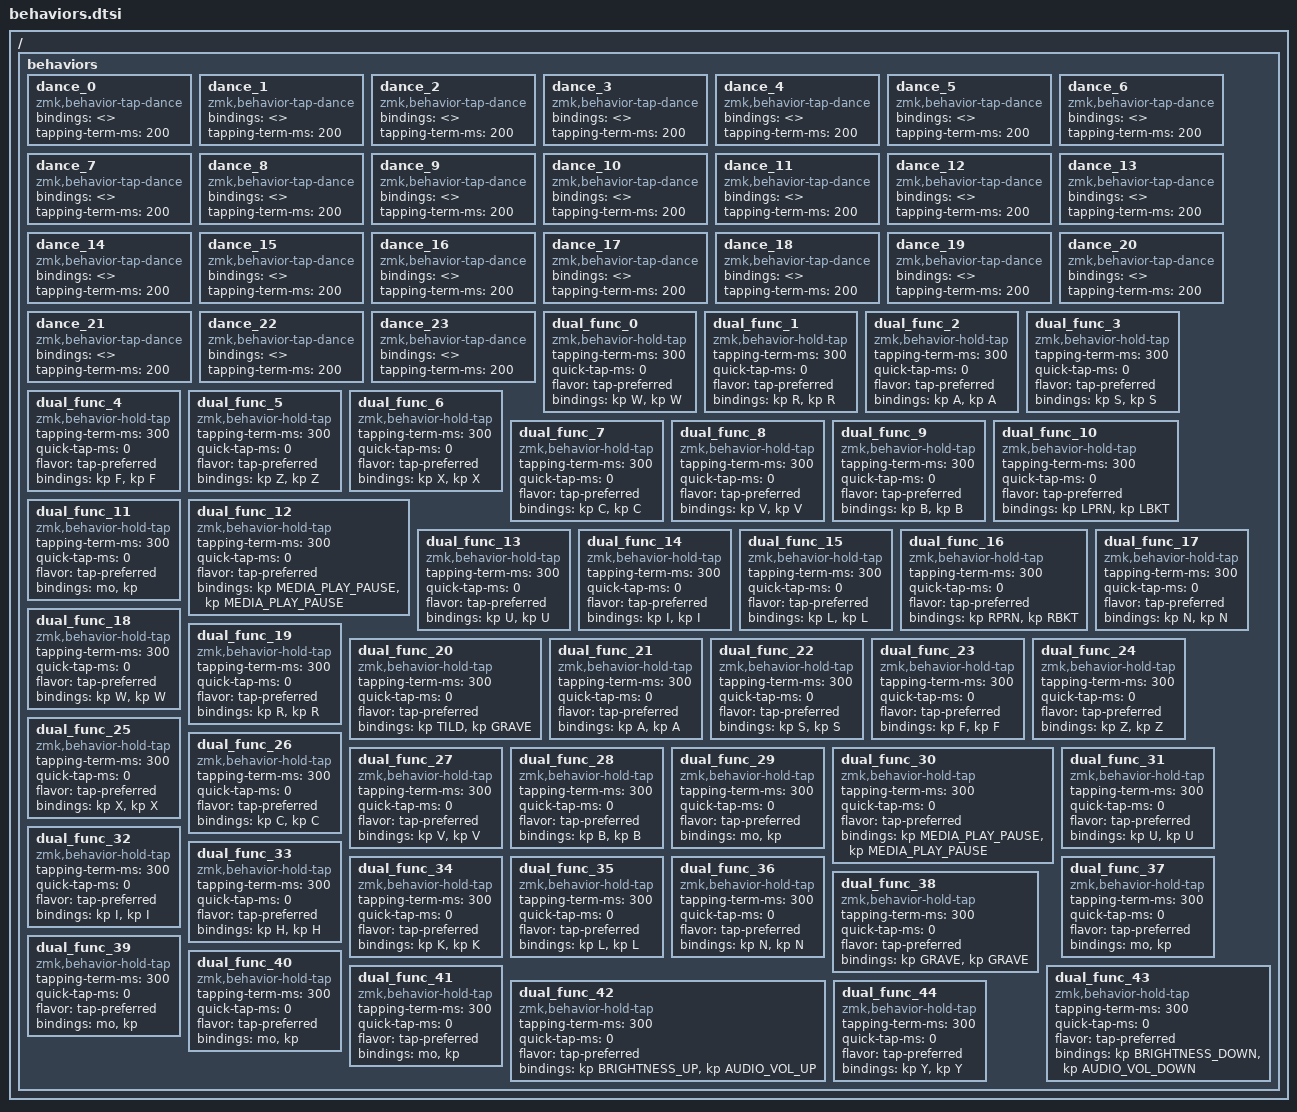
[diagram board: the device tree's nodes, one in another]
// Auto-generated by qmk_to_zmk.py - Complete behaviors conversion
#include <dt-bindings/zmk/keys.h>

/ {
    behaviors {
        dance_0: dance_0 {
            compatible = "zmk,behavior-tap-dance";
            #binding-cells = <0>;
            bindings = <>;
            tapping-term-ms = <200>;
        };

        dance_1: dance_1 {
            compatible = "zmk,behavior-tap-dance";
            #binding-cells = <0>;
            bindings = <>;
            tapping-term-ms = <200>;
        };

        dance_2: dance_2 {
            compatible = "zmk,behavior-tap-dance";
            #binding-cells = <0>;
            bindings = <>;
            tapping-term-ms = <200>;
        };

        dance_3: dance_3 {
            compatible = "zmk,behavior-tap-dance";
            #binding-cells = <0>;
            bindings = <>;
            tapping-term-ms = <200>;
        };

        dance_4: dance_4 {
            compatible = "zmk,behavior-tap-dance";
            #binding-cells = <0>;
            bindings = <>;
            tapping-term-ms = <200>;
        };

        dance_5: dance_5 {
            compatible = "zmk,behavior-tap-dance";
            #binding-cells = <0>;
            bindings = <>;
            tapping-term-ms = <200>;
        };

        dance_6: dance_6 {
            compatible = "zmk,behavior-tap-dance";
            #binding-cells = <0>;
            bindings = <>;
            tapping-term-ms = <200>;
        };

        dance_7: dance_7 {
            compatible = "zmk,behavior-tap-dance";
            #binding-cells = <0>;
            bindings = <>;
            tapping-term-ms = <200>;
        };

        dance_8: dance_8 {
            compatible = "zmk,behavior-tap-dance";
            #binding-cells = <0>;
            bindings = <>;
            tapping-term-ms = <200>;
        };

        dance_9: dance_9 {
            compatible = "zmk,behavior-tap-dance";
            #binding-cells = <0>;
            bindings = <>;
            tapping-term-ms = <200>;
        };

        dance_10: dance_10 {
            compatible = "zmk,behavior-tap-dance";
            #binding-cells = <0>;
            bindings = <>;
            tapping-term-ms = <200>;
        };

        dance_11: dance_11 {
            compatible = "zmk,behavior-tap-dance";
            #binding-cells = <0>;
            bindings = <>;
            tapping-term-ms = <200>;
        };

        dance_12: dance_12 {
            compatible = "zmk,behavior-tap-dance";
            #binding-cells = <0>;
            bindings = <>;
            tapping-term-ms = <200>;
        };

        dance_13: dance_13 {
            compatible = "zmk,behavior-tap-dance";
            #binding-cells = <0>;
            bindings = <>;
            tapping-term-ms = <200>;
        };

        dance_14: dance_14 {
            compatible = "zmk,behavior-tap-dance";
            #binding-cells = <0>;
            bindings = <>;
            tapping-term-ms = <200>;
        };

        dance_15: dance_15 {
            compatible = "zmk,behavior-tap-dance";
            #binding-cells = <0>;
            bindings = <>;
            tapping-term-ms = <200>;
        };

        dance_16: dance_16 {
            compatible = "zmk,behavior-tap-dance";
            #binding-cells = <0>;
            bindings = <>;
            tapping-term-ms = <200>;
        };

        dance_17: dance_17 {
            compatible = "zmk,behavior-tap-dance";
            #binding-cells = <0>;
            bindings = <>;
            tapping-term-ms = <200>;
        };

        dance_18: dance_18 {
            compatible = "zmk,behavior-tap-dance";
            #binding-cells = <0>;
            bindings = <>;
            tapping-term-ms = <200>;
        };

        dance_19: dance_19 {
            compatible = "zmk,behavior-tap-dance";
            #binding-cells = <0>;
            bindings = <>;
            tapping-term-ms = <200>;
        };

        dance_20: dance_20 {
            compatible = "zmk,behavior-tap-dance";
            #binding-cells = <0>;
            bindings = <>;
            tapping-term-ms = <200>;
        };

        dance_21: dance_21 {
            compatible = "zmk,behavior-tap-dance";
            #binding-cells = <0>;
            bindings = <>;
            tapping-term-ms = <200>;
        };

        dance_22: dance_22 {
            compatible = "zmk,behavior-tap-dance";
            #binding-cells = <0>;
            bindings = <>;
            tapping-term-ms = <200>;
        };

        dance_23: dance_23 {
            compatible = "zmk,behavior-tap-dance";
            #binding-cells = <0>;
            bindings = <>;
            tapping-term-ms = <200>;
        };

        dual_func_0: dual_func_0 {
            compatible = "zmk,behavior-hold-tap";
            #binding-cells = <2>;
            tapping-term-ms = <300>;
            quick-tap-ms = <0>;
            flavor = "tap-preferred";
            bindings = <&mo>, <&kp>;
        };

        dual_func_1: dual_func_1 {
            compatible = "zmk,behavior-hold-tap";
            #binding-cells = <2>;
            tapping-term-ms = <300>;
            quick-tap-ms = <0>;
            flavor = "tap-preferred";
            bindings = <&mo>, <&kp>;
        };

        dual_func_2: dual_func_2 {
            compatible = "zmk,behavior-hold-tap";
            #binding-cells = <2>;
            tapping-term-ms = <300>;
            quick-tap-ms = <0>;
            flavor = "tap-preferred";
            bindings = <&mo>, <&kp>;
        };

        dual_func_3: dual_func_3 {
            compatible = "zmk,behavior-hold-tap";
            #binding-cells = <2>;
            tapping-term-ms = <300>;
            quick-tap-ms = <0>;
            flavor = "tap-preferred";
            bindings = <&mo>, <&kp>;
        };

        dual_func_4: dual_func_4 {
            compatible = "zmk,behavior-hold-tap";
            #binding-cells = <2>;
            tapping-term-ms = <300>;
            quick-tap-ms = <0>;
            flavor = "tap-preferred";
            bindings = <&mo>, <&kp>;
        };

        dual_func_5: dual_func_5 {
            compatible = "zmk,behavior-hold-tap";
            #binding-cells = <2>;
            tapping-term-ms = <300>;
            quick-tap-ms = <0>;
            flavor = "tap-preferred";
            bindings = <&mo>, <&kp>;
        };

        dual_func_6: dual_func_6 {
            compatible = "zmk,behavior-hold-tap";
            #binding-cells = <2>;
            tapping-term-ms = <300>;
            quick-tap-ms = <0>;
            flavor = "tap-preferred";
            bindings = <&mo>, <&kp>;
        };

        dual_func_7: dual_func_7 {
            compatible = "zmk,behavior-hold-tap";
            #binding-cells = <2>;
            tapping-term-ms = <300>;
            quick-tap-ms = <0>;
            flavor = "tap-preferred";
            bindings = <&mo>, <&kp>;
        };

        dual_func_8: dual_func_8 {
            compatible = "zmk,behavior-hold-tap";
            #binding-cells = <2>;
            tapping-term-ms = <300>;
            quick-tap-ms = <0>;
            flavor = "tap-preferred";
            bindings = <&mo>, <&kp>;
        };

        dual_func_9: dual_func_9 {
            compatible = "zmk,behavior-hold-tap";
            #binding-cells = <2>;
            tapping-term-ms = <300>;
            quick-tap-ms = <0>;
            flavor = "tap-preferred";
            bindings = <&mo>, <&kp>;
        };

        dual_func_10: dual_func_10 {
            compatible = "zmk,behavior-hold-tap";
            #binding-cells = <2>;
            tapping-term-ms = <300>;
            quick-tap-ms = <0>;
            flavor = "tap-preferred";
            bindings = <&mo>, <&kp>;
        };

        dual_func_11: dual_func_11 {
            compatible = "zmk,behavior-hold-tap";
            #binding-cells = <2>;
            tapping-term-ms = <300>;
            quick-tap-ms = <0>;
            flavor = "tap-preferred";
            bindings = <&mo>, <&kp>;
        };

        dual_func_12: dual_func_12 {
            compatible = "zmk,behavior-hold-tap";
            #binding-cells = <2>;
            tapping-term-ms = <300>;
            quick-tap-ms = <0>;
            flavor = "tap-preferred";
            bindings = <&mo>, <&kp>;
        };

        dual_func_13: dual_func_13 {
            compatible = "zmk,behavior-hold-tap";
            #binding-cells = <2>;
            tapping-term-ms = <300>;
            quick-tap-ms = <0>;
            flavor = "tap-preferred";
            bindings = <&mo>, <&kp>;
        };

        dual_func_14: dual_func_14 {
            compatible = "zmk,behavior-hold-tap";
            #binding-cells = <2>;
            tapping-term-ms = <300>;
            quick-tap-ms = <0>;
            flavor = "tap-preferred";
            bindings = <&mo>, <&kp>;
        };

        dual_func_15: dual_func_15 {
            compatible = "zmk,behavior-hold-tap";
            #binding-cells = <2>;
            tapping-term-ms = <300>;
            quick-tap-ms = <0>;
            flavor = "tap-preferred";
            bindings = <&mo>, <&kp>;
        };

        dual_func_16: dual_func_16 {
            compatible = "zmk,behavior-hold-tap";
            #binding-cells = <2>;
            tapping-term-ms = <300>;
            quick-tap-ms = <0>;
            flavor = "tap-preferred";
            bindings = <&mo>, <&kp>;
        };

        dual_func_17: dual_func_17 {
            compatible = "zmk,behavior-hold-tap";
            #binding-cells = <2>;
            tapping-term-ms = <300>;
            quick-tap-ms = <0>;
            flavor = "tap-preferred";
            bindings = <&mo>, <&kp>;
        };

        dual_func_18: dual_func_18 {
            compatible = "zmk,behavior-hold-tap";
            #binding-cells = <2>;
            tapping-term-ms = <300>;
            quick-tap-ms = <0>;
            flavor = "tap-preferred";
            bindings = <&mo>, <&kp>;
        };

        dual_func_19: dual_func_19 {
            compatible = "zmk,behavior-hold-tap";
            #binding-cells = <2>;
            tapping-term-ms = <300>;
            quick-tap-ms = <0>;
            flavor = "tap-preferred";
            bindings = <&mo>, <&kp>;
        };

        dual_func_20: dual_func_20 {
            compatible = "zmk,behavior-hold-tap";
            #binding-cells = <2>;
            tapping-term-ms = <300>;
            quick-tap-ms = <0>;
            flavor = "tap-preferred";
            bindings = <&mo>, <&kp>;
        };

        dual_func_21: dual_func_21 {
            compatible = "zmk,behavior-hold-tap";
            #binding-cells = <2>;
            tapping-term-ms = <300>;
            quick-tap-ms = <0>;
            flavor = "tap-preferred";
            bindings = <&mo>, <&kp>;
        };

        dual_func_22: dual_func_22 {
            compatible = "zmk,behavior-hold-tap";
            #binding-cells = <2>;
            tapping-term-ms = <300>;
            quick-tap-ms = <0>;
            flavor = "tap-preferred";
            bindings = <&mo>, <&kp>;
        };

        dual_func_23: dual_func_23 {
            compatible = "zmk,behavior-hold-tap";
            #binding-cells = <2>;
            tapping-term-ms = <300>;
            quick-tap-ms = <0>;
            flavor = "tap-preferred";
            bindings = <&mo>, <&kp>;
        };

        dual_func_24: dual_func_24 {
            compatible = "zmk,behavior-hold-tap";
            #binding-cells = <2>;
            tapping-term-ms = <300>;
            quick-tap-ms = <0>;
            flavor = "tap-preferred";
            bindings = <&mo>, <&kp>;
        };

        dual_func_25: dual_func_25 {
            compatible = "zmk,behavior-hold-tap";
            #binding-cells = <2>;
            tapping-term-ms = <300>;
            quick-tap-ms = <0>;
            flavor = "tap-preferred";
            bindings = <&mo>, <&kp>;
        };

        dual_func_26: dual_func_26 {
            compatible = "zmk,behavior-hold-tap";
            #binding-cells = <2>;
            tapping-term-ms = <300>;
            quick-tap-ms = <0>;
            flavor = "tap-preferred";
            bindings = <&mo>, <&kp>;
        };

        dual_func_27: dual_func_27 {
            compatible = "zmk,behavior-hold-tap";
            #binding-cells = <2>;
            tapping-term-ms = <300>;
            quick-tap-ms = <0>;
            flavor = "tap-preferred";
            bindings = <&mo>, <&kp>;
        };

        dual_func_28: dual_func_28 {
            compatible = "zmk,behavior-hold-tap";
            #binding-cells = <2>;
            tapping-term-ms = <300>;
            quick-tap-ms = <0>;
            flavor = "tap-preferred";
            bindings = <&mo>, <&kp>;
        };

        dual_func_29: dual_func_29 {
            compatible = "zmk,behavior-hold-tap";
            #binding-cells = <2>;
            tapping-term-ms = <300>;
            quick-tap-ms = <0>;
            flavor = "tap-preferred";
            bindings = <&mo>, <&kp>;
        };

        dual_func_30: dual_func_30 {
            compatible = "zmk,behavior-hold-tap";
            #binding-cells = <2>;
            tapping-term-ms = <300>;
            quick-tap-ms = <0>;
            flavor = "tap-preferred";
            bindings = <&mo>, <&kp>;
        };

        dual_func_31: dual_func_31 {
            compatible = "zmk,behavior-hold-tap";
            #binding-cells = <2>;
            tapping-term-ms = <300>;
            quick-tap-ms = <0>;
            flavor = "tap-preferred";
            bindings = <&mo>, <&kp>;
        };

        dual_func_32: dual_func_32 {
            compatible = "zmk,behavior-hold-tap";
            #binding-cells = <2>;
            tapping-term-ms = <300>;
            quick-tap-ms = <0>;
            flavor = "tap-preferred";
            bindings = <&mo>, <&kp>;
        };

        dual_func_33: dual_func_33 {
            compatible = "zmk,behavior-hold-tap";
            #binding-cells = <2>;
            tapping-term-ms = <300>;
            quick-tap-ms = <0>;
            flavor = "tap-preferred";
            bindings = <&mo>, <&kp>;
        };

        dual_func_34: dual_func_34 {
            compatible = "zmk,behavior-hold-tap";
            #binding-cells = <2>;
            tapping-term-ms = <300>;
            quick-tap-ms = <0>;
            flavor = "tap-preferred";
            bindings = <&mo>, <&kp>;
        };

        dual_func_35: dual_func_35 {
            compatible = "zmk,behavior-hold-tap";
            #binding-cells = <2>;
            tapping-term-ms = <300>;
            quick-tap-ms = <0>;
            flavor = "tap-preferred";
            bindings = <&mo>, <&kp>;
        };

        dual_func_36: dual_func_36 {
            compatible = "zmk,behavior-hold-tap";
            #binding-cells = <2>;
            tapping-term-ms = <300>;
            quick-tap-ms = <0>;
            flavor = "tap-preferred";
            bindings = <&mo>, <&kp>;
        };

        dual_func_37: dual_func_37 {
            compatible = "zmk,behavior-hold-tap";
            #binding-cells = <2>;
            tapping-term-ms = <300>;
            quick-tap-ms = <0>;
            flavor = "tap-preferred";
            bindings = <&mo>, <&kp>;
        };

        dual_func_38: dual_func_38 {
            compatible = "zmk,behavior-hold-tap";
            #binding-cells = <2>;
            tapping-term-ms = <300>;
            quick-tap-ms = <0>;
            flavor = "tap-preferred";
            bindings = <&mo>, <&kp>;
        };

        dual_func_39: dual_func_39 {
            compatible = "zmk,behavior-hold-tap";
            #binding-cells = <2>;
            tapping-term-ms = <300>;
            quick-tap-ms = <0>;
            flavor = "tap-preferred";
            bindings = <&mo>, <&kp>;
        };

        dual_func_40: dual_func_40 {
            compatible = "zmk,behavior-hold-tap";
            #binding-cells = <2>;
            tapping-term-ms = <300>;
            quick-tap-ms = <0>;
            flavor = "tap-preferred";
            bindings = <&mo>, <&kp>;
        };

        dual_func_41: dual_func_41 {
            compatible = "zmk,behavior-hold-tap";
            #binding-cells = <2>;
            tapping-term-ms = <300>;
            quick-tap-ms = <0>;
            flavor = "tap-preferred";
            bindings = <&mo>, <&kp>;
        };

        dual_func_42: dual_func_42 {
            compatible = "zmk,behavior-hold-tap";
            #binding-cells = <2>;
            tapping-term-ms = <300>;
            quick-tap-ms = <0>;
            flavor = "tap-preferred";
            bindings = <&mo>, <&kp>;
        };

        dual_func_43: dual_func_43 {
            compatible = "zmk,behavior-hold-tap";
            #binding-cells = <2>;
            tapping-term-ms = <300>;
            quick-tap-ms = <0>;
            flavor = "tap-preferred";
            bindings = <&mo>, <&kp>;
        };

        dual_func_44: dual_func_44 {
            compatible = "zmk,behavior-hold-tap";
            #binding-cells = <2>;
            tapping-term-ms = <300>;
            quick-tap-ms = <0>;
            flavor = "tap-preferred";
            bindings = <&mo>, <&kp>;
        };

        dual_func_0: dual_func_0 {
            compatible = "zmk,behavior-hold-tap";
            #binding-cells = <2>;
            tapping-term-ms = <300>;
            quick-tap-ms = <0>;
            flavor = "tap-preferred";
            bindings = <&kp W>, <&kp W>;
        };

        dual_func_1: dual_func_1 {
            compatible = "zmk,behavior-hold-tap";
            #binding-cells = <2>;
            tapping-term-ms = <300>;
            quick-tap-ms = <0>;
            flavor = "tap-preferred";
            bindings = <&kp R>, <&kp R>;
        };

        dual_func_2: dual_func_2 {
            compatible = "zmk,behavior-hold-tap";
            #binding-cells = <2>;
            tapping-term-ms = <300>;
            quick-tap-ms = <0>;
            flavor = "tap-preferred";
            bindings = <&kp A>, <&kp A>;
        };

        dual_func_3: dual_func_3 {
            compatible = "zmk,behavior-hold-tap";
            #binding-cells = <2>;
            tapping-term-ms = <300>;
            quick-tap-ms = <0>;
            flavor = "tap-preferred";
            bindings = <&kp S>, <&kp S>;
        };

        dual_func_4: dual_func_4 {
            compatible = "zmk,behavior-hold-tap";
            #binding-cells = <2>;
            tapping-term-ms = <300>;
            quick-tap-ms = <0>;
            flavor = "tap-preferred";
            bindings = <&kp F>, <&kp F>;
        };

        dual_func_5: dual_func_5 {
            compatible = "zmk,behavior-hold-tap";
            #binding-cells = <2>;
            tapping-term-ms = <300>;
            quick-tap-ms = <0>;
            flavor = "tap-preferred";
            bindings = <&kp Z>, <&kp Z>;
        };

        dual_func_6: dual_func_6 {
            compatible = "zmk,behavior-hold-tap";
            #binding-cells = <2>;
            tapping-term-ms = <300>;
            quick-tap-ms = <0>;
            flavor = "tap-preferred";
            bindings = <&kp X>, <&kp X>;
        };

        dual_func_7: dual_func_7 {
            compatible = "zmk,behavior-hold-tap";
            #binding-cells = <2>;
            tapping-term-ms = <300>;
            quick-tap-ms = <0>;
            flavor = "tap-preferred";
            bindings = <&kp C>, <&kp C>;
        };

        dual_func_8: dual_func_8 {
            compatible = "zmk,behavior-hold-tap";
            #binding-cells = <2>;
            tapping-term-ms = <300>;
            quick-tap-ms = <0>;
            flavor = "tap-preferred";
            bindings = <&kp V>, <&kp V>;
        };

        dual_func_9: dual_func_9 {
            compatible = "zmk,behavior-hold-tap";
            #binding-cells = <2>;
            tapping-term-ms = <300>;
            quick-tap-ms = <0>;
            flavor = "tap-preferred";
            bindings = <&kp B>, <&kp B>;
        };

        dual_func_10: dual_func_10 {
            compatible = "zmk,behavior-hold-tap";
            #binding-cells = <2>;
            tapping-term-ms = <300>;
            quick-tap-ms = <0>;
            flavor = "tap-preferred";
            bindings = <&kp LPRN>, <&kp LBKT>;
        };

        dual_func_12: dual_func_12 {
            compatible = "zmk,behavior-hold-tap";
            #binding-cells = <2>;
            tapping-term-ms = <300>;
            quick-tap-ms = <0>;
            flavor = "tap-preferred";
            bindings = <&kp MEDIA_PLAY_PAUSE>, <&kp MEDIA_PLAY_PAUSE>;
        };

        dual_func_13: dual_func_13 {
            compatible = "zmk,behavior-hold-tap";
            #binding-cells = <2>;
            tapping-term-ms = <300>;
            quick-tap-ms = <0>;
            flavor = "tap-preferred";
            bindings = <&kp U>, <&kp U>;
        };

        dual_func_14: dual_func_14 {
            compatible = "zmk,behavior-hold-tap";
            #binding-cells = <2>;
            tapping-term-ms = <300>;
            quick-tap-ms = <0>;
            flavor = "tap-preferred";
            bindings = <&kp I>, <&kp I>;
        };

        dual_func_15: dual_func_15 {
            compatible = "zmk,behavior-hold-tap";
            #binding-cells = <2>;
            tapping-term-ms = <300>;
            quick-tap-ms = <0>;
            flavor = "tap-preferred";
            bindings = <&kp L>, <&kp L>;
        };

        dual_func_16: dual_func_16 {
            compatible = "zmk,behavior-hold-tap";
            #binding-cells = <2>;
            tapping-term-ms = <300>;
            quick-tap-ms = <0>;
            flavor = "tap-preferred";
            bindings = <&kp RPRN>, <&kp RBKT>;
        };

        dual_func_17: dual_func_17 {
            compatible = "zmk,behavior-hold-tap";
            #binding-cells = <2>;
            tapping-term-ms = <300>;
            quick-tap-ms = <0>;
            flavor = "tap-preferred";
            bindings = <&kp N>, <&kp N>;
        };

        dual_func_18: dual_func_18 {
            compatible = "zmk,behavior-hold-tap";
            #binding-cells = <2>;
            tapping-term-ms = <300>;
            quick-tap-ms = <0>;
            flavor = "tap-preferred";
            bindings = <&kp W>, <&kp W>;
        };

        dual_func_19: dual_func_19 {
            compatible = "zmk,behavior-hold-tap";
            #binding-cells = <2>;
            tapping-term-ms = <300>;
            quick-tap-ms = <0>;
            flavor = "tap-preferred";
            bindings = <&kp R>, <&kp R>;
        };

        dual_func_20: dual_func_20 {
            compatible = "zmk,behavior-hold-tap";
            #binding-cells = <2>;
            tapping-term-ms = <300>;
            quick-tap-ms = <0>;
            flavor = "tap-preferred";
            bindings = <&kp TILD>, <&kp GRAVE>;
        };

        dual_func_21: dual_func_21 {
            compatible = "zmk,behavior-hold-tap";
            #binding-cells = <2>;
            tapping-term-ms = <300>;
            quick-tap-ms = <0>;
            flavor = "tap-preferred";
            bindings = <&kp A>, <&kp A>;
        };

        dual_func_22: dual_func_22 {
            compatible = "zmk,behavior-hold-tap";
            #binding-cells = <2>;
            tapping-term-ms = <300>;
            quick-tap-ms = <0>;
            flavor = "tap-preferred";
            bindings = <&kp S>, <&kp S>;
        };

        dual_func_23: dual_func_23 {
            compatible = "zmk,behavior-hold-tap";
            #binding-cells = <2>;
            tapping-term-ms = <300>;
            quick-tap-ms = <0>;
            flavor = "tap-preferred";
            bindings = <&kp F>, <&kp F>;
        };

        dual_func_24: dual_func_24 {
            compatible = "zmk,behavior-hold-tap";
            #binding-cells = <2>;
            tapping-term-ms = <300>;
            quick-tap-ms = <0>;
            flavor = "tap-preferred";
            bindings = <&kp Z>, <&kp Z>;
        };

        dual_func_25: dual_func_25 {
            compatible = "zmk,behavior-hold-tap";
            #binding-cells = <2>;
            tapping-term-ms = <300>;
            quick-tap-ms = <0>;
            flavor = "tap-preferred";
            bindings = <&kp X>, <&kp X>;
        };

        dual_func_26: dual_func_26 {
            compatible = "zmk,behavior-hold-tap";
            #binding-cells = <2>;
            tapping-term-ms = <300>;
            quick-tap-ms = <0>;
            flavor = "tap-preferred";
            bindings = <&kp C>, <&kp C>;
        };

        dual_func_27: dual_func_27 {
            compatible = "zmk,behavior-hold-tap";
            #binding-cells = <2>;
            tapping-term-ms = <300>;
            quick-tap-ms = <0>;
            flavor = "tap-preferred";
            bindings = <&kp V>, <&kp V>;
        };

        dual_func_28: dual_func_28 {
            compatible = "zmk,behavior-hold-tap";
            #binding-cells = <2>;
            tapping-term-ms = <300>;
            quick-tap-ms = <0>;
            flavor = "tap-preferred";
            bindings = <&kp B>, <&kp B>;
        };

        dual_func_30: dual_func_30 {
            compatible = "zmk,behavior-hold-tap";
            #binding-cells = <2>;
            tapping-term-ms = <300>;
            quick-tap-ms = <0>;
            flavor = "tap-preferred";
            bindings = <&kp MEDIA_PLAY_PAUSE>, <&kp MEDIA_PLAY_PAUSE>;
        };

        dual_func_31: dual_func_31 {
            compatible = "zmk,behavior-hold-tap";
            #binding-cells = <2>;
            tapping-term-ms = <300>;
            quick-tap-ms = <0>;
            flavor = "tap-preferred";
            bindings = <&kp U>, <&kp U>;
        };

        dual_func_32: dual_func_32 {
            compatible = "zmk,behavior-hold-tap";
            #binding-cells = <2>;
            tapping-term-ms = <300>;
            quick-tap-ms = <0>;
            flavor = "tap-preferred";
            bindings = <&kp I>, <&kp I>;
        };

        dual_func_33: dual_func_33 {
            compatible = "zmk,behavior-hold-tap";
            #binding-cells = <2>;
            tapping-term-ms = <300>;
            quick-tap-ms = <0>;
            flavor = "tap-preferred";
            bindings = <&kp H>, <&kp H>;
        };

        dual_func_34: dual_func_34 {
            compatible = "zmk,behavior-hold-tap";
            #binding-cells = <2>;
            tapping-term-ms = <300>;
            quick-tap-ms = <0>;
            flavor = "tap-preferred";
            bindings = <&kp K>, <&kp K>;
        };

        dual_func_35: dual_func_35 {
            compatible = "zmk,behavior-hold-tap";
            #binding-cells = <2>;
            tapping-term-ms = <300>;
            quick-tap-ms = <0>;
            flavor = "tap-preferred";
            bindings = <&kp L>, <&kp L>;
        };

        dual_func_36: dual_func_36 {
            compatible = "zmk,behavior-hold-tap";
            #binding-cells = <2>;
            tapping-term-ms = <300>;
            quick-tap-ms = <0>;
            flavor = "tap-preferred";
            bindings = <&kp N>, <&kp N>;
        };

        dual_func_38: dual_func_38 {
            compatible = "zmk,behavior-hold-tap";
            #binding-cells = <2>;
            tapping-term-ms = <300>;
            quick-tap-ms = <0>;
            flavor = "tap-preferred";
            bindings = <&kp GRAVE>, <&kp GRAVE>;
        };

        dual_func_42: dual_func_42 {
            compatible = "zmk,behavior-hold-tap";
            #binding-cells = <2>;
            tapping-term-ms = <300>;
            quick-tap-ms = <0>;
            flavor = "tap-preferred";
            bindings = <&kp BRIGHTNESS_UP>, <&kp AUDIO_VOL_UP>;
        };

        dual_func_43: dual_func_43 {
            compatible = "zmk,behavior-hold-tap";
            #binding-cells = <2>;
            tapping-term-ms = <300>;
            quick-tap-ms = <0>;
            flavor = "tap-preferred";
            bindings = <&kp BRIGHTNESS_DOWN>, <&kp AUDIO_VOL_DOWN>;
        };

        dual_func_44: dual_func_44 {
            compatible = "zmk,behavior-hold-tap";
            #binding-cells = <2>;
            tapping-term-ms = <300>;
            quick-tap-ms = <0>;
            flavor = "tap-preferred";
            bindings = <&kp Y>, <&kp Y>;
        };

    };
};
